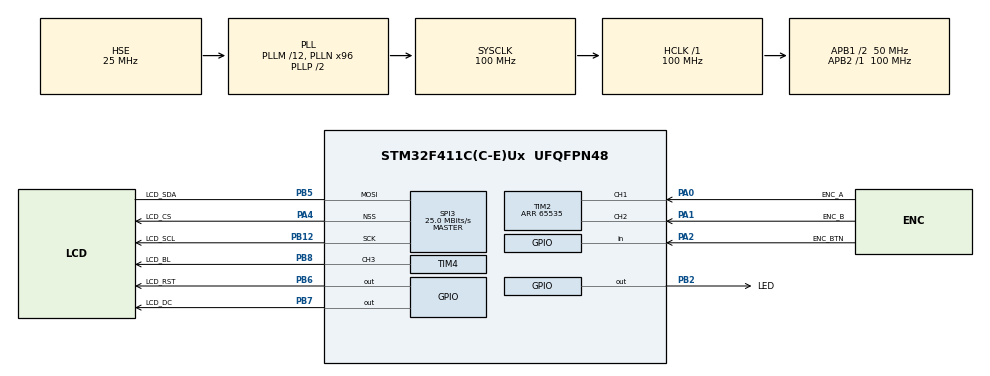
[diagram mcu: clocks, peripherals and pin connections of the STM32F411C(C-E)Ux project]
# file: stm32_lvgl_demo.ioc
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Dma.Request0=SPI3_TX
Dma.SPI3_TX.0.Direction=DMA_MEMORY_TO_PERIPH
Dma.SPI3_TX.0.FIFOMode=DMA_FIFOMODE_DISABLE
Dma.SPI3_TX.0.Instance=DMA1_Stream5
Dma.SPI3_TX.0.MemDataAlignment=DMA_MDATAALIGN_BYTE
Dma.SPI3_TX.0.MemInc=DMA_MINC_ENABLE
Dma.SPI3_TX.0.Mode=DMA_NORMAL
Dma.SPI3_TX.0.PeriphDataAlignment=DMA_PDATAALIGN_BYTE
Dma.SPI3_TX.0.PeriphInc=DMA_PINC_DISABLE
Dma.SPI3_TX.0.Priority=DMA_PRIORITY_LOW
FREERTOS.Tasks01=defaultTask,0,128,StartDefaultTask,Default,NULL,Dynamic,NULL,NULL
FREERTOS.configUSE_NEWLIB_REENTRANT=1
FREERTOS.configUSE_RECURSIVE_MUTEXES=1
Mcu.Family=STM32F4
Mcu.Name=STM32F411C(C-E)Ux
Mcu.Package=UFQFPN48
NVIC.DMA1_Stream5_IRQn=true\:5\:0\:false\:false\:true\:true\:false\:true\:true
NVIC.PriorityGroup=NVIC_PRIORITYGROUP_4
NVIC.SPI3_IRQn=true\:5\:0\:false\:false\:true\:true\:true\:true\:true
NVIC.TIM1_UP_TIM10_IRQn=true\:15\:0\:false\:false\:true\:false\:false\:true\:true
NVIC.TimeBase=TIM1_UP_TIM10_IRQn
NVIC.TimeBaseIP=TIM1
PA0-WKUP.GPIO_Label=ENC_A
PA0-WKUP.Signal=S_TIM2_CH1_ETR
PA1.GPIO_Label=ENC_B
PA1.Signal=S_TIM2_CH2
PA13.Mode=Serial_Wire
PA13.Signal=SYS_JTMS-SWDIO
PA14.Mode=Serial_Wire
PA14.Signal=SYS_JTCK-SWCLK
PA2.GPIO_Label=ENC_BTN
PA2.Signal=GPIO_Input
PA4.GPIO_Label=LCD_CS
PA4.Mode=NSS_Signal_Hard_Output
PA4.Signal=SPI3_NSS
PB12.GPIO_Label=LCD_SCL
PB12.Mode=Simplex_Bidirectional_Master
PB12.Signal=SPI3_SCK
PB2.GPIO_Label=LED
PB2.PinState=GPIO_PIN_SET
PB2.Signal=GPIO_Output
PB5.GPIO_Label=LCD_SDA
PB5.Mode=Simplex_Bidirectional_Master
PB5.Signal=SPI3_MOSI
PB6.GPIO_Label=LCD_RST
PB6.GPIO_Speed=GPIO_SPEED_FREQ_HIGH
PB6.PinState=GPIO_PIN_RESET
PB6.Signal=GPIO_Output
PB7.GPIO_Label=LCD_DC
PB7.GPIO_Speed=GPIO_SPEED_FREQ_HIGH
PB7.Signal=GPIO_Output
PB8.GPIO_Label=LCD_BL
PB8.Signal=S_TIM4_CH3
PH0\ -\ OSC_IN.Mode=HSE-External-Oscillator
PH0\ -\ OSC_IN.Signal=RCC_OSC_IN
PH1\ -\ OSC_OUT.Mode=HSE-External-Oscillator
PH1\ -\ OSC_OUT.Signal=RCC_OSC_OUT
ProjectManager.HeapSize=0x200
ProjectManager.StackSize=0x400
ProjectManager.TargetToolchain=CMake
RCC.48MHZClocksFreq_Value=50000000
RCC.AHBFreq_Value=100000000
RCC.APB1CLKDivider=RCC_HCLK_DIV2
RCC.APB1Freq_Value=50000000
RCC.APB1TimFreq_Value=100000000
RCC.APB2Freq_Value=100000000
RCC.APB2TimFreq_Value=100000000
RCC.CortexFreq_Value=100000000
RCC.HCLKFreq_Value=100000000
RCC.HSE_VALUE=25000000
RCC.HSI_VALUE=16000000
RCC.LSE_VALUE=32768
RCC.PLLM=12
RCC.PLLN=96
RCC.PLLSourceVirtual=RCC_PLLSOURCE_HSE
RCC.SYSCLKFreq_VALUE=100000000
RCC.SYSCLKSource=RCC_SYSCLKSOURCE_PLLCLK
RCC.VCOOutputFreq_Value=200000000
SH.S_TIM2_CH1_ETR.0=TIM2_CH1,Encoder_Interface
SH.S_TIM2_CH2.0=TIM2_CH2,Encoder_Interface
SH.S_TIM4_CH3.0=TIM4_CH3,PWM Generation3 CH3
SPI3.BaudRatePrescaler=SPI_BAUDRATEPRESCALER_2
SPI3.CalculateBaudRate=25.0 MBits/s
SPI3.Direction=SPI_DIRECTION_1LINE
SPI3.Mode=SPI_MODE_MASTER
SPI3.VirtualNSS=VM_NSSHARD
SPI3.VirtualType=VM_MASTER
TIM2.AutoReloadPreload=TIM_AUTORELOAD_PRELOAD_ENABLE
TIM2.EncoderMode=TIM_ENCODERMODE_TI12
TIM2.IC1Filter=10
TIM2.Period=65535
TIM4.Channel-PWM\ Generation3\ CH3=TIM_CHANNEL_3
TIM4.Period=100-1
TIM4.Prescaler=100-1
VP_FREERTOS_VS_CMSIS_V1.Mode=CMSIS_V1
VP_SYS_VS_tim1.Mode=TIM1
board=custom

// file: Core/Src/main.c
/* USER CODE BEGIN Header */
/**
  ******************************************************************************
  * @file           : main.c
  * @brief          : Main program body
  ******************************************************************************
  * @attention
  *
  * Copyright (c) 2024 STMicroelectronics.
  * All rights reserved.
  *
  * This software is licensed under terms that can be found in the LICENSE file
  * in the root directory of this software component.
  * If no LICENSE file comes with this software, it is provided AS-IS.
  *
  ******************************************************************************
  */
/* USER CODE END Header */
#include "main.h"
#include "cmsis_os.h"

/* USER CODE BEGIN Includes */

#include "ui/ui.h"

/* USER CODE END Includes */

SPI_HandleTypeDef hspi3;
DMA_HandleTypeDef hdma_spi3_tx;

TIM_HandleTypeDef htim2;
TIM_HandleTypeDef htim4;

osThreadId defaultTaskHandle;

void SystemClock_Config(void);
static void MX_GPIO_Init(void);
static void MX_DMA_Init(void);
static void MX_SPI3_Init(void);
static void MX_TIM2_Init(void);
static void MX_TIM4_Init(void);
void StartDefaultTask(void const * argument);

/* USER CODE BEGIN 0 */

void HAL_SPI_TxCpltCallback(SPI_HandleTypeDef *hspi)
{
    if (hspi == &hspi3)
    {
        st7735_dma_done();
    }
}

void HAL_SPI_ErrorCallback(SPI_HandleTypeDef *hspi)
{
    if (hspi == &hspi3)
    {
        st7735_dma_done();
    }
}

/* USER CODE END 0 */

int main(void)
{

  /* MCU Configuration--------------------------------------------------------*/

  /* Reset of all peripherals, Initializes the Flash interface and the Systick. */
  HAL_Init();

  /* Configure the system clock */
  SystemClock_Config();

  /* Initialize all configured peripherals */
  MX_GPIO_Init();
  MX_DMA_Init();
  MX_SPI3_Init();
  MX_TIM2_Init();
  MX_TIM4_Init();

  /* Create the thread(s) */
  /* definition and creation of defaultTask */
  osThreadDef(defaultTask, StartDefaultTask, osPriorityNormal, 0, 128);
  defaultTaskHandle = osThreadCreate(osThread(defaultTask), NULL);

  /* USER CODE BEGIN RTOS_THREADS */
  ui_create_task();
  /* USER CODE END RTOS_THREADS */

  /* Start scheduler */
  osKernelStart();

  /* We should never get here as control is now taken by the scheduler */

  /* Infinite loop */
  while (1)
  {

  }
}

void SystemClock_Config(void)
{
  RCC_OscInitTypeDef RCC_OscInitStruct = {0};
  RCC_ClkInitTypeDef RCC_ClkInitStruct = {0};

  /** Configure the main internal regulator output voltage
  */
  __HAL_RCC_PWR_CLK_ENABLE();
  __HAL_PWR_VOLTAGESCALING_CONFIG(PWR_REGULATOR_VOLTAGE_SCALE1);

  /** Initializes the RCC Oscillators according to the specified parameters
  * in the RCC_OscInitTypeDef structure.
  */
  RCC_OscInitStruct.OscillatorType = RCC_OSCILLATORTYPE_HSE;
  RCC_OscInitStruct.HSEState = RCC_HSE_ON;
  RCC_OscInitStruct.PLL.PLLState = RCC_PLL_ON;
  RCC_OscInitStruct.PLL.PLLSource = RCC_PLLSOURCE_HSE;
  RCC_OscInitStruct.PLL.PLLM = 12;
  RCC_OscInitStruct.PLL.PLLN = 96;
  RCC_OscInitStruct.PLL.PLLP = RCC_PLLP_DIV2;
  RCC_OscInitStruct.PLL.PLLQ = 4;
  if (HAL_RCC_OscConfig(&RCC_OscInitStruct) != HAL_OK)
  {
    Error_Handler();
  }

  /** Initializes the CPU, AHB and APB buses clocks
  */
  RCC_ClkInitStruct.ClockType = RCC_CLOCKTYPE_HCLK|RCC_CLOCKTYPE_SYSCLK
                              |RCC_CLOCKTYPE_PCLK1|RCC_CLOCKTYPE_PCLK2;
  RCC_ClkInitStruct.SYSCLKSource = RCC_SYSCLKSOURCE_PLLCLK;
  RCC_ClkInitStruct.AHBCLKDivider = RCC_SYSCLK_DIV1;
  RCC_ClkInitStruct.APB1CLKDivider = RCC_HCLK_DIV2;
  RCC_ClkInitStruct.APB2CLKDivider = RCC_HCLK_DIV1;

  if (HAL_RCC_ClockConfig(&RCC_ClkInitStruct, FLASH_LATENCY_3) != HAL_OK)
  {
    Error_Handler();
  }
}

static void MX_SPI3_Init(void)
{

  /* SPI3 parameter configuration*/
  hspi3.Instance = SPI3;
  hspi3.Init.Mode = SPI_MODE_MASTER;
  hspi3.Init.Direction = SPI_DIRECTION_1LINE;
  hspi3.Init.DataSize = SPI_DATASIZE_8BIT;
  hspi3.Init.CLKPolarity = SPI_POLARITY_LOW;
  hspi3.Init.CLKPhase = SPI_PHASE_1EDGE;
  hspi3.Init.NSS = SPI_NSS_HARD_OUTPUT;
  hspi3.Init.BaudRatePrescaler = SPI_BAUDRATEPRESCALER_2;
  hspi3.Init.FirstBit = SPI_FIRSTBIT_MSB;
  hspi3.Init.TIMode = SPI_TIMODE_DISABLE;
  hspi3.Init.CRCCalculation = SPI_CRCCALCULATION_DISABLE;
  hspi3.Init.CRCPolynomial = 10;
  if (HAL_SPI_Init(&hspi3) != HAL_OK)
  {
    Error_Handler();
  }

}

static void MX_TIM2_Init(void)
{

  TIM_Encoder_InitTypeDef sConfig = {0};
  TIM_MasterConfigTypeDef sMasterConfig = {0};

  htim2.Instance = TIM2;
  htim2.Init.Prescaler = 0;
  htim2.Init.CounterMode = TIM_COUNTERMODE_UP;
  htim2.Init.Period = 65535;
  htim2.Init.ClockDivision = TIM_CLOCKDIVISION_DIV1;
  htim2.Init.AutoReloadPreload = TIM_AUTORELOAD_PRELOAD_ENABLE;
  sConfig.EncoderMode = TIM_ENCODERMODE_TI12;
  sConfig.IC1Polarity = TIM_ICPOLARITY_RISING;
  sConfig.IC1Selection = TIM_ICSELECTION_DIRECTTI;
  sConfig.IC1Prescaler = TIM_ICPSC_DIV1;
  sConfig.IC1Filter = 10;
  sConfig.IC2Polarity = TIM_ICPOLARITY_RISING;
  sConfig.IC2Selection = TIM_ICSELECTION_DIRECTTI;
  sConfig.IC2Prescaler = TIM_ICPSC_DIV1;
  sConfig.IC2Filter = 0;
  if (HAL_TIM_Encoder_Init(&htim2, &sConfig) != HAL_OK)
  {
    Error_Handler();
  }
  sMasterConfig.MasterOutputTrigger = TIM_TRGO_RESET;
  sMasterConfig.MasterSlaveMode = TIM_MASTERSLAVEMODE_DISABLE;
  if (HAL_TIMEx_MasterConfigSynchronization(&htim2, &sMasterConfig) != HAL_OK)
  {
    Error_Handler();
  }

}

static void MX_TIM4_Init(void)
{

  TIM_MasterConfigTypeDef sMasterConfig = {0};
  TIM_OC_InitTypeDef sConfigOC = {0};

  htim4.Instance = TIM4;
  htim4.Init.Prescaler = 100-1;
  htim4.Init.CounterMode = TIM_COUNTERMODE_UP;
  htim4.Init.Period = 100-1;
  htim4.Init.ClockDivision = TIM_CLOCKDIVISION_DIV1;
  htim4.Init.AutoReloadPreload = TIM_AUTORELOAD_PRELOAD_DISABLE;
  if (HAL_TIM_PWM_Init(&htim4) != HAL_OK)
  {
    Error_Handler();
  }
  sMasterConfig.MasterOutputTrigger = TIM_TRGO_RESET;
  sMasterConfig.MasterSlaveMode = TIM_MASTERSLAVEMODE_DISABLE;
  if (HAL_TIMEx_MasterConfigSynchronization(&htim4, &sMasterConfig) != HAL_OK)
  {
    Error_Handler();
  }
  sConfigOC.OCMode = TIM_OCMODE_PWM1;
  sConfigOC.Pulse = 0;
  sConfigOC.OCPolarity = TIM_OCPOLARITY_HIGH;
  sConfigOC.OCFastMode = TIM_OCFAST_DISABLE;
  if (HAL_TIM_PWM_ConfigChannel(&htim4, &sConfigOC, TIM_CHANNEL_3) != HAL_OK)
  {
    Error_Handler();
  }
  HAL_TIM_MspPostInit(&htim4);

}

static void MX_DMA_Init(void)
{

  /* DMA controller clock enable */
  __HAL_RCC_DMA1_CLK_ENABLE();

  /* DMA interrupt init */
  /* DMA1_Stream5_IRQn interrupt configuration */
  HAL_NVIC_SetPriority(DMA1_Stream5_IRQn, 5, 0);
  HAL_NVIC_EnableIRQ(DMA1_Stream5_IRQn);

}

static void MX_GPIO_Init(void)
{
  GPIO_InitTypeDef GPIO_InitStruct = {0};

  /* GPIO Ports Clock Enable */
  __HAL_RCC_GPIOH_CLK_ENABLE();
  __HAL_RCC_GPIOA_CLK_ENABLE();
  __HAL_RCC_GPIOB_CLK_ENABLE();

  /*Configure GPIO pin Output Level */
  HAL_GPIO_WritePin(LED_GPIO_Port, LED_Pin, GPIO_PIN_SET);

  /*Configure GPIO pin Output Level */
  HAL_GPIO_WritePin(GPIOB, LCD_RST_Pin|LCD_DC_Pin, GPIO_PIN_RESET);

  /*Configure GPIO pin : ENC_BTN_Pin */
  GPIO_InitStruct.Pin = ENC_BTN_Pin;
  GPIO_InitStruct.Mode = GPIO_MODE_INPUT;
  GPIO_InitStruct.Pull = GPIO_NOPULL;
  HAL_GPIO_Init(ENC_BTN_GPIO_Port, &GPIO_InitStruct);

  /*Configure GPIO pin : LED_Pin */
  GPIO_InitStruct.Pin = LED_Pin;
  GPIO_InitStruct.Mode = GPIO_MODE_OUTPUT_PP;
  GPIO_InitStruct.Pull = GPIO_NOPULL;
  GPIO_InitStruct.Speed = GPIO_SPEED_FREQ_LOW;
  HAL_GPIO_Init(LED_GPIO_Port, &GPIO_InitStruct);

  /*Configure GPIO pins : LCD_RST_Pin LCD_DC_Pin */
  GPIO_InitStruct.Pin = LCD_RST_Pin|LCD_DC_Pin;
  GPIO_InitStruct.Mode = GPIO_MODE_OUTPUT_PP;
  GPIO_InitStruct.Pull = GPIO_NOPULL;
  GPIO_InitStruct.Speed = GPIO_SPEED_FREQ_HIGH;
  HAL_GPIO_Init(GPIOB, &GPIO_InitStruct);

}

void StartDefaultTask(void const * argument)
{
  for(;;)
  {
    osDelay(1);
  }
}

void HAL_TIM_PeriodElapsedCallback(TIM_HandleTypeDef *htim)
{
  if (htim->Instance == TIM1)
  {
    HAL_IncTick();
  }
}

void Error_Handler(void)
{
  __disable_irq();
  while (1)
  {
  }
}
